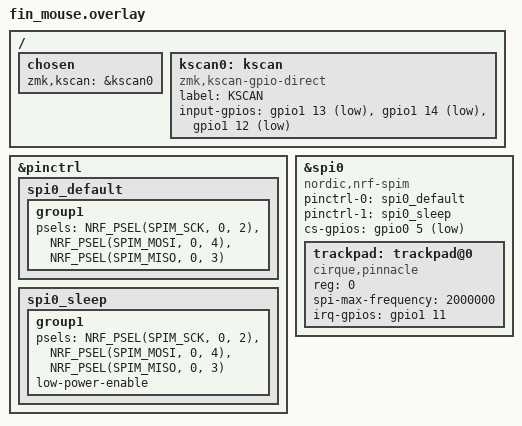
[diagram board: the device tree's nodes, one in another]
#include <dt-bindings/zmk/matrix_transform.h>

/ {
    chosen {
        zmk,kscan = &kscan0;
    };

    kscan0: kscan {
        compatible = "zmk,kscan-gpio-direct";
        label = "KSCAN";
        input-gpios
            = <&gpio1 13 (GPIO_ACTIVE_LOW | GPIO_PULL_UP)>  /* 좌클릭: P1.13 */
            , <&gpio1 14 (GPIO_ACTIVE_LOW | GPIO_PULL_UP)>  /* 우클릭: P1.14 */
            , <&gpio1 12 (GPIO_ACTIVE_LOW | GPIO_PULL_UP)>  /* 블루투스: P1.12 */
            ;
    };
};

/* SPI 핀 설정 (P0.02, P0.04, P0.03) */
&pinctrl {
    spi0_default: spi0_default {
        group1 {
            psels = <NRF_PSEL(SPIM_SCK, 0, 2)>,   /* SCK: P0.02 */
                    <NRF_PSEL(SPIM_MOSI, 0, 4)>,  /* MOSI: P0.04 */
                    <NRF_PSEL(SPIM_MISO, 0, 3)>;  /* MISO: P0.03 */
        };
    };

    spi0_sleep: spi0_sleep {
        group1 {
            psels = <NRF_PSEL(SPIM_SCK, 0, 2)>,
                    <NRF_PSEL(SPIM_MOSI, 0, 4)>,
                    <NRF_PSEL(SPIM_MISO, 0, 3)>;
            low-power-enable;
        };
    };
};

&spi0 {
    status = "okay";
    compatible = "nordic,nrf-spim";
    pinctrl-0 = <&spi0_default>;
    pinctrl-1 = <&spi0_sleep>;
    pinctrl-names = "default", "sleep";
    
    /* CS 핀: P0.05 */
    cs-gpios = <&gpio0 5 GPIO_ACTIVE_LOW>; 

    trackpad: trackpad@0 {
        compatible = "cirque,pinnacle";
        reg = <0>;
        spi-max-frequency = <2000000>;
        status = "okay";
        
        /* DR (Data Ready) 핀: P1.11 */
        irq-gpios = <&gpio1 11 (GPIO_ACTIVE_HIGH | GPIO_PULL_DOWN)>;
    };
};
